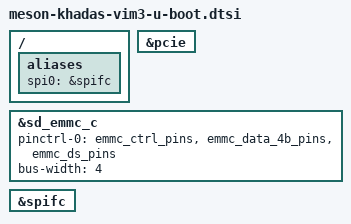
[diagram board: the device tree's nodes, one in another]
// SPDX-License-Identifier: (GPL-2.0+ OR MIT)
/*
 * Copyright (c) 2020 BayLibre, SAS
 * Author: Neil Armstrong <narmstrong@baylibre.com>
 */

/ {
	aliases {
		spi0 = &spifc;
	};
};

&pcie {
	status = "okay";
};

&sd_emmc_c {
	status = "okay";
	pinctrl-0 = <&emmc_ctrl_pins>, <&emmc_data_4b_pins>, <&emmc_ds_pins>;
	bus-width = <4>;
};

&spifc {
	status = "okay";
};
